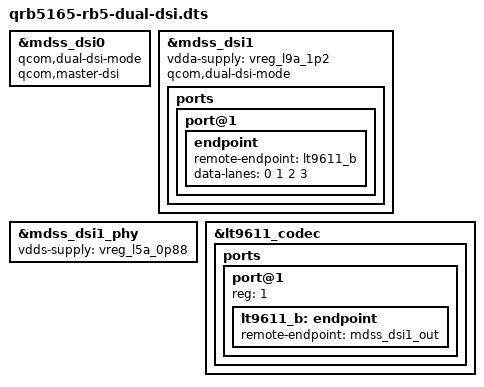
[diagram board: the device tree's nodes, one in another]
// SPDX-License-Identifier: BSD-3-Clause
/*
 * Copyright (c) 2020, Linaro Ltd.
 */

/dts-v1/;

#include "qrb5165-rb5.dts"

&mdss_dsi0 {
	qcom,dual-dsi-mode;
	qcom,master-dsi;
};

&mdss_dsi1 {
	status = "okay";
	vdda-supply = <&vreg_l9a_1p2>;

	qcom,dual-dsi-mode;

	ports {
		port@1 {
			endpoint {
				remote-endpoint = <&lt9611_b>;
				data-lanes = <0 1 2 3>;
			};
		};
	};
};

&mdss_dsi1_phy {
	status = "okay";
	vdds-supply = <&vreg_l5a_0p88>;
};

&lt9611_codec {
	ports {
		port@1 {
			reg = <1>;

			lt9611_b: endpoint {
				remote-endpoint = <&mdss_dsi1_out>;
			};
		};
	};
};
